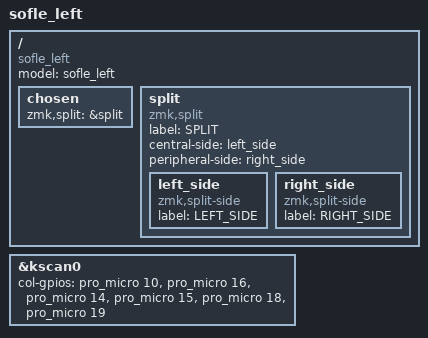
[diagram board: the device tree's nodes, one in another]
/*
 * Copyright (c) 2020 The ZMK Contributors
 *
 * SPDX-License-Identifier: MIT
 */

#include "sofle.dtsi"

/ {
    model = "sofle_left";
    compatible = "sofle_left";

    chosen {
        zmk,split = &split;
    };

    split: split {
        compatible = "zmk,split";
        label = "SPLIT";
        
        central-side = <&left_side>;
        peripheral-side = <&right_side>;
        
        left_side: left_side {
            compatible = "zmk,split-side";
            label = "LEFT_SIDE";
        };
        
        right_side: right_side {
            compatible = "zmk,split-side";
            label = "RIGHT_SIDE";
        };
    };
};

&kscan0 {
    col-gpios
        = <&pro_micro 10 (GPIO_ACTIVE_HIGH | GPIO_PULL_DOWN)>
        , <&pro_micro 16 (GPIO_ACTIVE_HIGH | GPIO_PULL_DOWN)>
        , <&pro_micro 14 (GPIO_ACTIVE_HIGH | GPIO_PULL_DOWN)>
        , <&pro_micro 15 (GPIO_ACTIVE_HIGH | GPIO_PULL_DOWN)>
        , <&pro_micro 18 (GPIO_ACTIVE_HIGH | GPIO_PULL_DOWN)>
        , <&pro_micro 19 (GPIO_ACTIVE_HIGH | GPIO_PULL_DOWN)>
        ;
};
